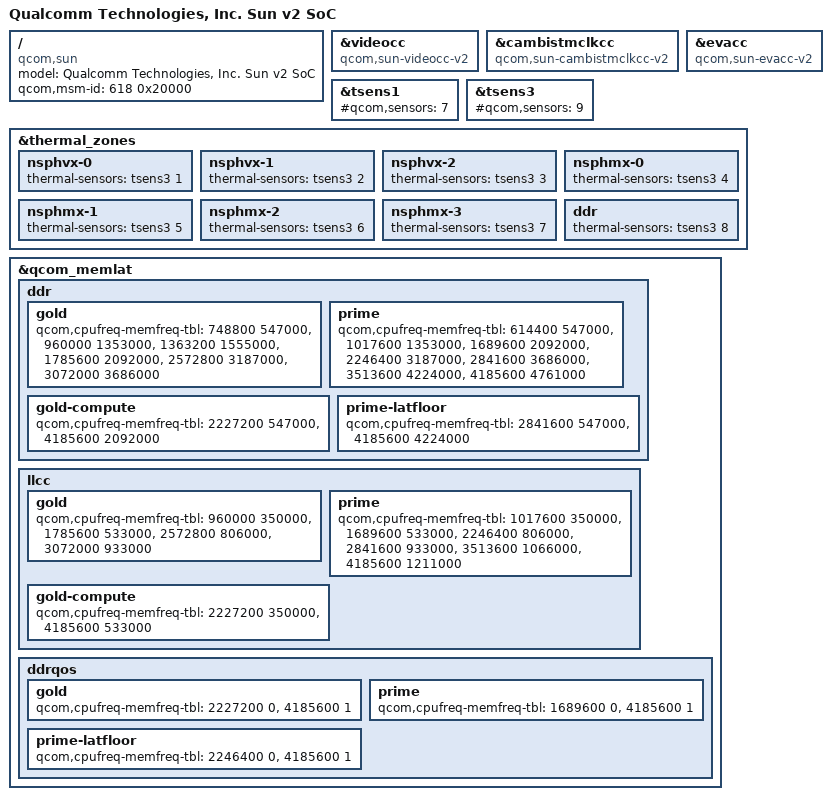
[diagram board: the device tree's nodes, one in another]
// SPDX-License-Identifier: BSD-3-Clause
/*
 * Copyright (c) 2023-2024, Qualcomm Innovation Center, Inc. All rights reserved.
 */
#include "sun.dtsi"

/ {
	model = "Qualcomm Technologies, Inc. Sun v2 SoC";
	compatible = "qcom,sun";
	qcom,msm-id = <618 0x20000>;
};

&videocc {
	compatible = "qcom,sun-videocc-v2", "syscon";
};

&cambistmclkcc {
	compatible = "qcom,sun-cambistmclkcc-v2", "syscon";
};

&evacc {
	compatible = "qcom,sun-evacc-v2", "syscon";
};

&tsens1 {
	#qcom,sensors = <7>;
};

&tsens3 {
	#qcom,sensors = <9>;
};

&thermal_zones {
	nsphvx-0 {
		thermal-sensors = <&tsens3 1>;
	};

	nsphvx-1 {
		thermal-sensors = <&tsens3 2>;
	};

	nsphvx-2 {
		thermal-sensors = <&tsens3 3>;
	};

	nsphmx-0 {
		thermal-sensors = <&tsens3 4>;
	};

	nsphmx-1 {
		thermal-sensors = <&tsens3 5>;
	};

	nsphmx-2 {
		thermal-sensors = <&tsens3 6>;
	};

	nsphmx-3 {
		thermal-sensors = <&tsens3 7>;
	};

	ddr {
		thermal-sensors = <&tsens3 8>;
	};
};

&qcom_memlat {
	ddr {
		gold {
			qcom,cpufreq-memfreq-tbl =
				<  748800  547000 >,
				<  960000 1353000 >,
				< 1363200 1555000 >,
				< 1785600 2092000 >,
				< 2572800 3187000 >,
				< 3072000 3686000 >;
		};

		prime {
			qcom,cpufreq-memfreq-tbl =
				<  614400  547000 >,
				< 1017600 1353000 >,
				< 1689600 2092000 >,
				< 2246400 3187000 >,
				< 2841600 3686000 >,
				< 3513600 4224000 >,
				< 4185600 4761000 >;
		};

		gold-compute {
			qcom,cpufreq-memfreq-tbl =
				< 2227200  547000 >,
				< 4185600 2092000 >;
		};

		prime-latfloor {
			qcom,cpufreq-memfreq-tbl =
				< 2841600  547000 >,
				< 4185600 4224000 >;
		};
	};

	llcc {
		gold {
			qcom,cpufreq-memfreq-tbl =
				<  960000  350000 >,
				< 1785600  533000 >,
				< 2572800  806000 >,
				< 3072000  933000 >;
		};

		prime {
			qcom,cpufreq-memfreq-tbl =
				< 1017600  350000 >,
				< 1689600  533000 >,
				< 2246400  806000 >,
				< 2841600  933000 >,
				< 3513600 1066000 >,
				< 4185600 1211000 >;
		};

		gold-compute {
			qcom,cpufreq-memfreq-tbl =
				< 2227200  350000 >,
				< 4185600  533000 >;
		};
	};

	ddrqos {
		gold {
			qcom,cpufreq-memfreq-tbl =
				< 2227200 0 >,
				< 4185600 1 >;
		};

		prime {
			qcom,cpufreq-memfreq-tbl =
				< 1689600 0 >,
				< 4185600 1 >;
		};

		prime-latfloor {
			qcom,cpufreq-memfreq-tbl =
				< 2246400 0 >,
				< 4185600 1 >;
		};
	};
};
